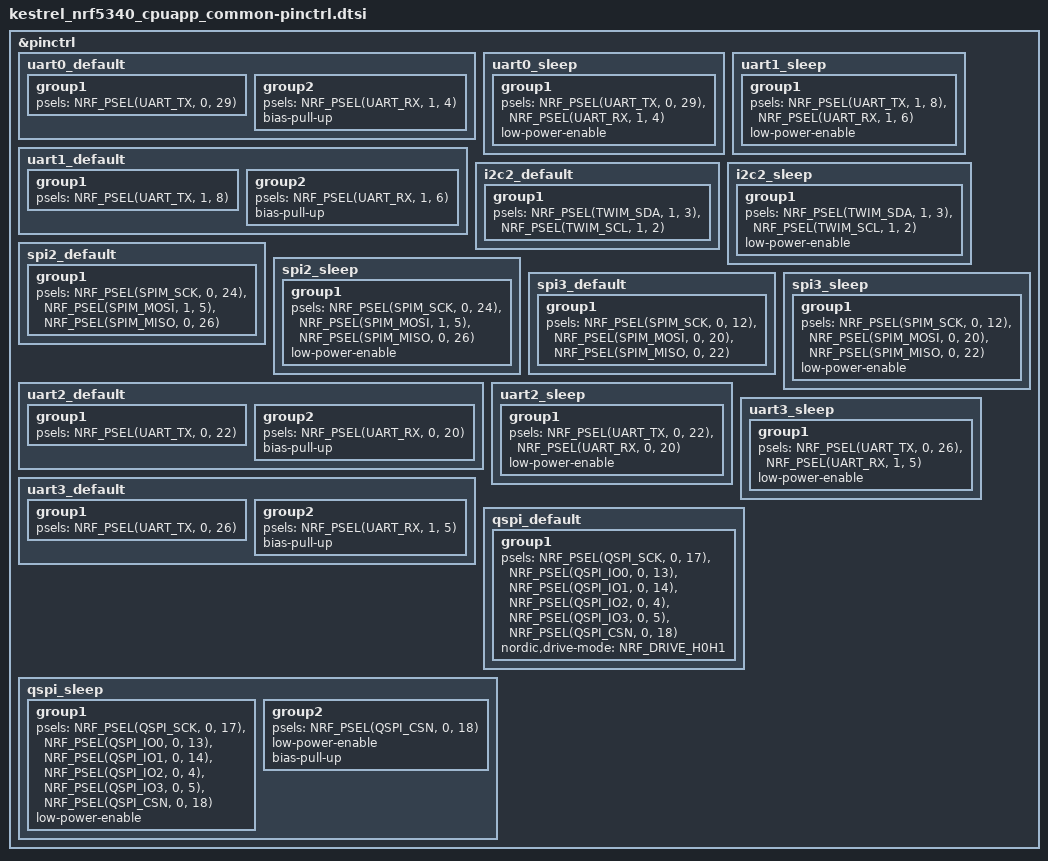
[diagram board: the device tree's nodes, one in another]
/*
 * Copyright (c) 2024 Nordic Semiconductor
 * SPDX-License-Identifier: LicenseRef-Nordic-5-Clause
 */

&pinctrl {
	uart0_default: uart0_default {
		group1 {
			psels = <NRF_PSEL(UART_TX, 0, 29)>;
		};
		group2 {
			psels = <NRF_PSEL(UART_RX, 1, 4)>;
			bias-pull-up;
		};
	};

	uart0_sleep: uart0_sleep {
		group1 {
			psels = <NRF_PSEL(UART_TX, 0, 29)>,
				<NRF_PSEL(UART_RX, 1, 4)>;
			low-power-enable;
		};
	};

	uart1_default: uart1_default {
		group1 {
			psels = <NRF_PSEL(UART_TX, 1, 8)>;
		};
		group2 {
			psels = <NRF_PSEL(UART_RX, 1, 6)>;
			bias-pull-up;
		};
	};

	uart1_sleep: uart1_sleep {
		group1 {
			psels = <NRF_PSEL(UART_TX, 1, 8)>,
				<NRF_PSEL(UART_RX, 1, 6)>;
			low-power-enable;
		};
	};

	i2c2_default: i2c2_default {
		group1 {
			psels = <NRF_PSEL(TWIM_SDA, 1, 3)>,
				<NRF_PSEL(TWIM_SCL, 1, 2)>;
		};
	};

	i2c2_sleep: i2c2_sleep {
		group1 {
			psels = <NRF_PSEL(TWIM_SDA, 1, 3)>,
				<NRF_PSEL(TWIM_SCL, 1, 2)>;
			low-power-enable;
		};
	};

	spi2_default: spi2_default {
		group1 {
			psels = <NRF_PSEL(SPIM_SCK, 0, 24)>,
				<NRF_PSEL(SPIM_MOSI, 1, 5)>,
				<NRF_PSEL(SPIM_MISO, 0, 26)>;
		};
	};

	spi2_sleep: spi2_sleep {
		group1 {
			psels = <NRF_PSEL(SPIM_SCK, 0, 24)>,
				<NRF_PSEL(SPIM_MOSI, 1, 5)>,
				<NRF_PSEL(SPIM_MISO, 0, 26)>;
			low-power-enable;
		};
	};


	spi3_default: spi3_default {
		group1 {
			psels = <NRF_PSEL(SPIM_SCK, 0, 12)>,
				<NRF_PSEL(SPIM_MOSI, 0, 20)>,
				<NRF_PSEL(SPIM_MISO, 0, 22)>;
		};
	};

	spi3_sleep: spi3_sleep {
	
		group1 {
			psels = <NRF_PSEL(SPIM_SCK, 0, 12)>,
				<NRF_PSEL(SPIM_MOSI, 0, 20)>,
				<NRF_PSEL(SPIM_MISO, 0, 22)>;
			low-power-enable;
		};
	};

	uart2_default: uart2_default {
		group1 {
			psels = <NRF_PSEL(UART_TX, 0, 22)>;
		};
		group2 {
			psels = <NRF_PSEL(UART_RX, 0, 20)>;
			bias-pull-up;
		};
	};

	uart2_sleep: uart2_sleep {
		group1 {
			psels = <NRF_PSEL(UART_TX, 0, 22)>,
				<NRF_PSEL(UART_RX, 0, 20)>;
			low-power-enable;
		};
	};

	uart3_default: uart3_default {
		group1 {
			psels = <NRF_PSEL(UART_TX, 0, 26)>;
		};
		group2 {
			psels = <NRF_PSEL(UART_RX, 1, 5)>;
			bias-pull-up;
		};
	};

	uart3_sleep: uart3_sleep {
		group1 {
			psels = <NRF_PSEL(UART_TX, 0, 26)>,
				<NRF_PSEL(UART_RX, 1, 5)>;
			low-power-enable;
		};
	};

	qspi_default: qspi_default {
		group1 {
			psels = <NRF_PSEL(QSPI_SCK, 0, 17)>,
				<NRF_PSEL(QSPI_IO0, 0, 13)>,
				<NRF_PSEL(QSPI_IO1, 0, 14)>,
				<NRF_PSEL(QSPI_IO2, 0, 4)>,
				<NRF_PSEL(QSPI_IO3, 0, 5)>,
				<NRF_PSEL(QSPI_CSN, 0, 18)>;
				nordic,drive-mode = <NRF_DRIVE_H0H1>;
		};
	};

	qspi_sleep: qspi_sleep {
		group1 {
			psels = <NRF_PSEL(QSPI_SCK, 0, 17)>,
				<NRF_PSEL(QSPI_IO0, 0, 13)>,
				<NRF_PSEL(QSPI_IO1, 0, 14)>,
				<NRF_PSEL(QSPI_IO2, 0, 4)>,
				<NRF_PSEL(QSPI_IO3, 0, 5)>,
				<NRF_PSEL(QSPI_CSN, 0, 18)>;
			low-power-enable;
		};
		group2 {
			psels = <NRF_PSEL(QSPI_CSN, 0, 18)>;
			low-power-enable;
			bias-pull-up;
		};
	};
};
